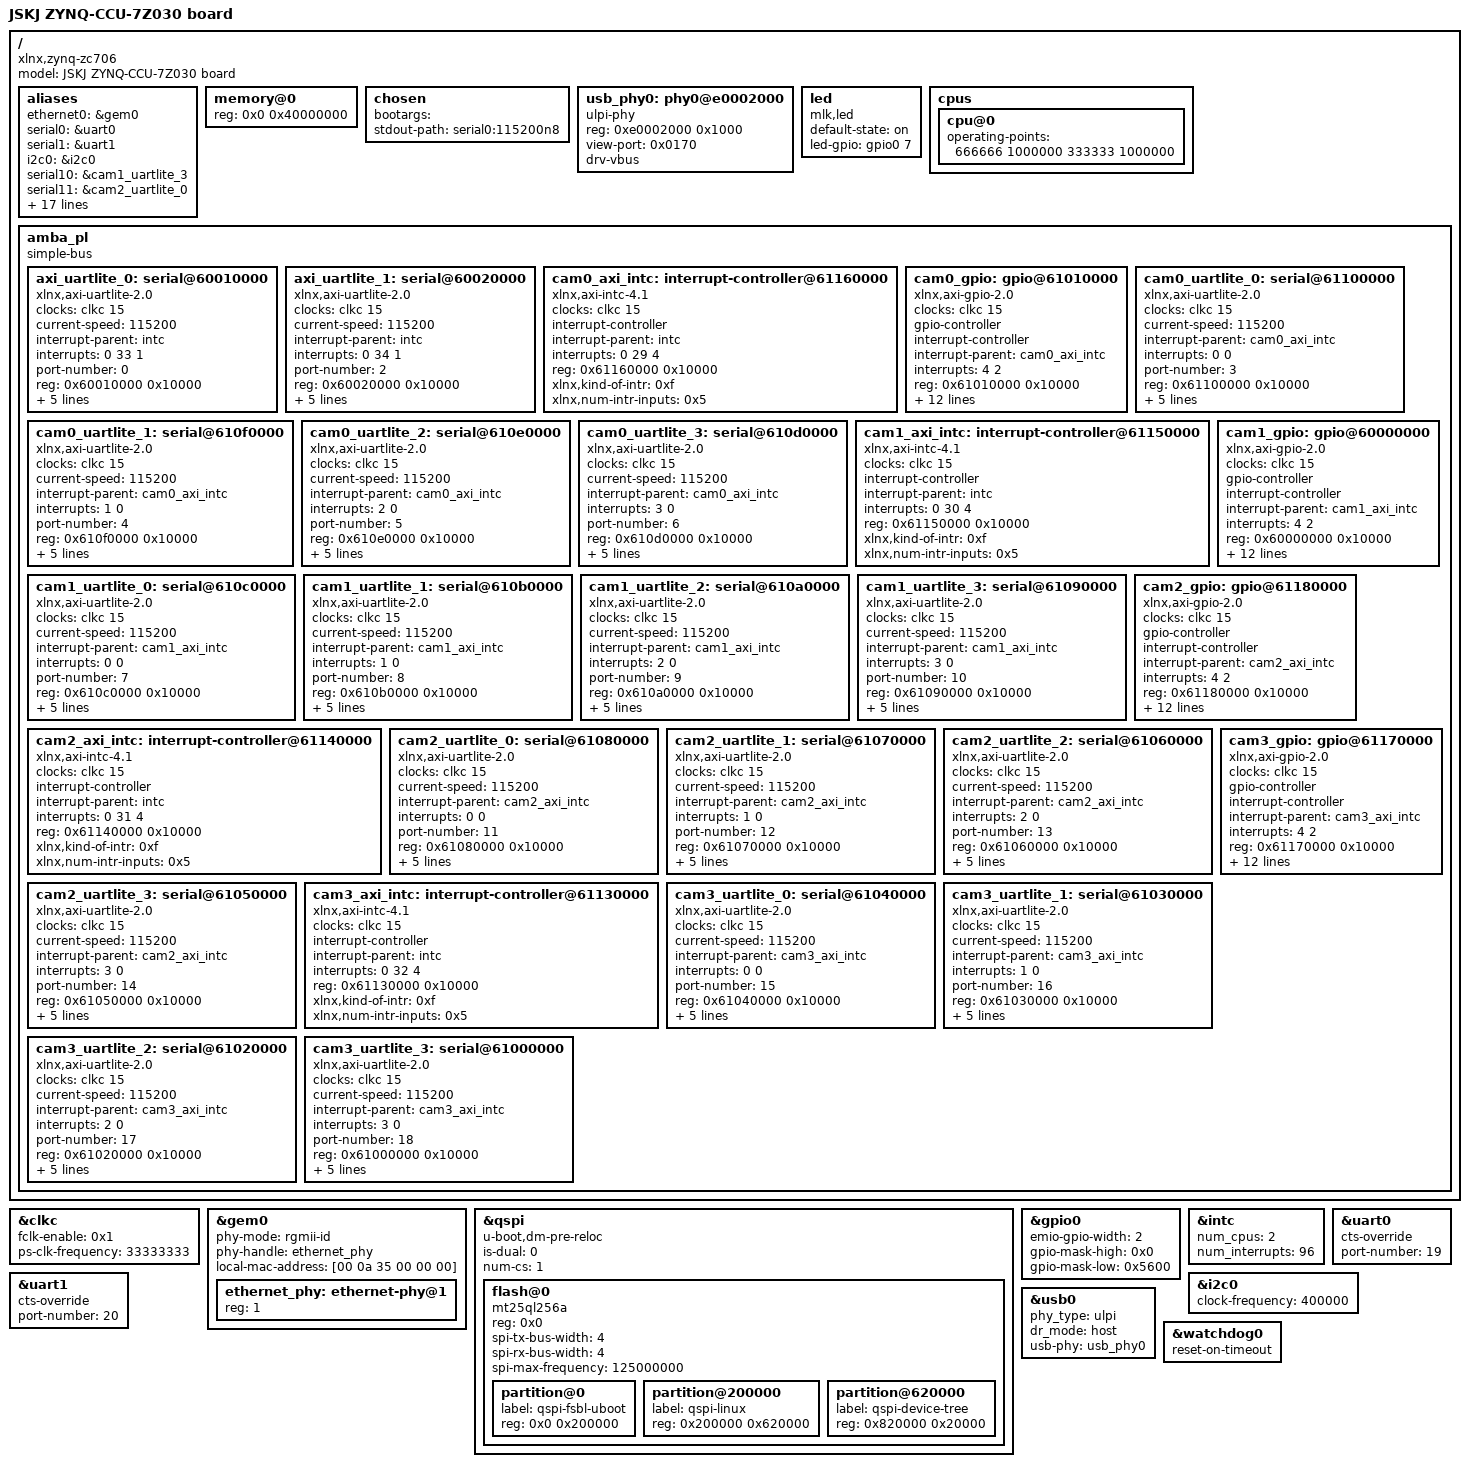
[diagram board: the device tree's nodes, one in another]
// SPDX-License-Identifier: GPL-2.0+
/*
 *  Copyright (C) 2011 - 2015 Xilinx
 *  Copyright (C) 2012 National Instruments Corp.
 */
#define GPIO_ACTIVE_HIGH 0
#define GPIO_ACTIVE_LOW 1

/dts-v1/;
#include "zynq-7000.dtsi"

/ {
	model = "JSKJ ZYNQ-CCU-7Z030 board";
	compatible = "xlnx,zynq-zc706", "xlnx,zynq-7000";

	aliases {
		ethernet0 = &gem0;
		serial0 = &uart0;
		serial1 = &uart1;
		i2c0 = &i2c0;
		serial10 = &cam1_uartlite_3;
		serial11 = &cam2_uartlite_0;
		serial12 = &cam2_uartlite_1;
		serial13 = &cam2_uartlite_2;
		serial14 = &cam2_uartlite_3;
		serial15 = &cam3_uartlite_0;
		serial16 = &cam3_uartlite_1;
		serial17 = &cam3_uartlite_2;
		serial18 = &cam3_uartlite_3;
		serial19 = &axi_uartlite_1;
		serial2 = &axi_uartlite_0;
		serial3 = &cam0_uartlite_0;
		serial4 = &cam0_uartlite_1;
		serial5 = &cam0_uartlite_2;
		serial6 = &cam0_uartlite_3;
		serial7 = &cam1_uartlite_0;
		serial8 = &cam1_uartlite_1;
		serial9 = &cam1_uartlite_2;
		spi0 = &qspi;
	};

	memory@0 {
		device_type = "memory";
		reg = <0x0 0x40000000>;
	};

	chosen {
		bootargs = "";
		stdout-path = "serial0:115200n8";
	};

	usb_phy0: phy0@e0002000 {
		compatible = "ulpi-phy";
		#phy-cells = <0>;
		reg = <0xe0002000 0x1000>;
		view-port = <0x0170>;
		drv-vbus;
	};

	led {
		compatible="mlk,led";
		status="okay";
		default-state="on";

		led-gpio = <&gpio0 7 GPIO_ACTIVE_HIGH>;
	};
};

/ {
	cpus {
		cpu@0 {
			operating-points = <666666 1000000 333333 1000000>;
		};
	};
};

/ {
	amba_pl: amba_pl {
		#address-cells = <1>;
		#size-cells = <1>;
		compatible = "simple-bus";
		ranges ;
		axi_uartlite_0: serial@60010000 {
			clock-names = "s_axi_aclk";
			clocks = <&clkc 15>;
			compatible = "xlnx,axi-uartlite-2.0", "xlnx,xps-uartlite-1.00.a";
			current-speed = <115200>;
			device_type = "serial";
			interrupt-names = "interrupt";
			interrupt-parent = <&intc>;
			interrupts = <0 33 1>;
			port-number = <0>;
			reg = <0x60010000 0x10000>;
			xlnx,baudrate = <0x1c200>;
			xlnx,data-bits = <0x8>;
			xlnx,odd-parity = <0x0>;
			xlnx,s-axi-aclk-freq-hz-d = "111.111115";
			xlnx,use-parity = <0x0>;
		};
		axi_uartlite_1: serial@60020000 {
			clock-names = "s_axi_aclk";
			clocks = <&clkc 15>;
			compatible = "xlnx,axi-uartlite-2.0", "xlnx,xps-uartlite-1.00.a";
			current-speed = <115200>;
			device_type = "serial";
			interrupt-names = "interrupt";
			interrupt-parent = <&intc>;
			interrupts = <0 34 1>;
			port-number = <2>;
			reg = <0x60020000 0x10000>;
			xlnx,baudrate = <0x1c200>;
			xlnx,data-bits = <0x8>;
			xlnx,odd-parity = <0x0>;
			xlnx,s-axi-aclk-freq-hz-d = "111.111115";
			xlnx,use-parity = <0x0>;
		};
		cam0_axi_intc: interrupt-controller@61160000 {
			#interrupt-cells = <2>;
			clock-names = "s_axi_aclk";
			clocks = <&clkc 15>;
			compatible = "xlnx,axi-intc-4.1", "xlnx,xps-intc-1.00.a";
			interrupt-controller ;
			interrupt-names = "irq";
			interrupt-parent = <&intc>;
			interrupts = <0 29 4>;
			reg = <0x61160000 0x10000>;
			xlnx,kind-of-intr = <0xf>;
			xlnx,num-intr-inputs = <0x5>;
		};
		cam0_gpio: gpio@61010000 {
			#gpio-cells = <2>;
			#interrupt-cells = <2>;
			clock-names = "s_axi_aclk";
			clocks = <&clkc 15>;
			compatible = "xlnx,axi-gpio-2.0", "xlnx,xps-gpio-1.00.a";
			gpio-controller ;
			interrupt-controller ;
			interrupt-names = "ip2intc_irpt";
			interrupt-parent = <&cam0_axi_intc>;
			interrupts = <4 2>;
			reg = <0x61010000 0x10000>;
			xlnx,all-inputs = <0x0>;
			xlnx,all-inputs-2 = <0x0>;
			xlnx,all-outputs = <0x0>;
			xlnx,all-outputs-2 = <0x0>;
			xlnx,dout-default = <0x00000000>;
			xlnx,dout-default-2 = <0x00000000>;
			xlnx,gpio-width = <0x8>;
			xlnx,gpio2-width = <0x20>;
			xlnx,interrupt-present = <0x1>;
			xlnx,is-dual = <0x0>;
			xlnx,tri-default = <0xFFFFFFFF>;
			xlnx,tri-default-2 = <0xFFFFFFFF>;
		};
		cam0_uartlite_0: serial@61100000 {
			clock-names = "s_axi_aclk";
			clocks = <&clkc 15>;
			compatible = "xlnx,axi-uartlite-2.0", "xlnx,xps-uartlite-1.00.a";
			current-speed = <115200>;
			device_type = "serial";
			interrupt-names = "interrupt";
			interrupt-parent = <&cam0_axi_intc>;
			interrupts = <0 0>;
			port-number = <3>;
			reg = <0x61100000 0x10000>;
			xlnx,baudrate = <0x1c200>;
			xlnx,data-bits = <0x8>;
			xlnx,odd-parity = <0x0>;
			xlnx,s-axi-aclk-freq-hz-d = "111.111115";
			xlnx,use-parity = <0x0>;
		};
		cam0_uartlite_1: serial@610f0000 {
			clock-names = "s_axi_aclk";
			clocks = <&clkc 15>;
			compatible = "xlnx,axi-uartlite-2.0", "xlnx,xps-uartlite-1.00.a";
			current-speed = <115200>;
			device_type = "serial";
			interrupt-names = "interrupt";
			interrupt-parent = <&cam0_axi_intc>;
			interrupts = <1 0>;
			port-number = <4>;
			reg = <0x610f0000 0x10000>;
			xlnx,baudrate = <0x1c200>;
			xlnx,data-bits = <0x8>;
			xlnx,odd-parity = <0x0>;
			xlnx,s-axi-aclk-freq-hz-d = "111.111115";
			xlnx,use-parity = <0x0>;
		};
		cam0_uartlite_2: serial@610e0000 {
			clock-names = "s_axi_aclk";
			clocks = <&clkc 15>;
			compatible = "xlnx,axi-uartlite-2.0", "xlnx,xps-uartlite-1.00.a";
			current-speed = <115200>;
			device_type = "serial";
			interrupt-names = "interrupt";
			interrupt-parent = <&cam0_axi_intc>;
			interrupts = <2 0>;
			port-number = <5>;
			reg = <0x610e0000 0x10000>;
			xlnx,baudrate = <0x1c200>;
			xlnx,data-bits = <0x8>;
			xlnx,odd-parity = <0x0>;
			xlnx,s-axi-aclk-freq-hz-d = "111.111115";
			xlnx,use-parity = <0x0>;
		};
		cam0_uartlite_3: serial@610d0000 {
			clock-names = "s_axi_aclk";
			clocks = <&clkc 15>;
			compatible = "xlnx,axi-uartlite-2.0", "xlnx,xps-uartlite-1.00.a";
			current-speed = <115200>;
			device_type = "serial";
			interrupt-names = "interrupt";
			interrupt-parent = <&cam0_axi_intc>;
			interrupts = <3 0>;
			port-number = <6>;
			reg = <0x610d0000 0x10000>;
			xlnx,baudrate = <0x1c200>;
			xlnx,data-bits = <0x8>;
			xlnx,odd-parity = <0x0>;
			xlnx,s-axi-aclk-freq-hz-d = "111.111115";
			xlnx,use-parity = <0x0>;
		};
		cam1_axi_intc: interrupt-controller@61150000 {
			#interrupt-cells = <2>;
			clock-names = "s_axi_aclk";
			clocks = <&clkc 15>;
			compatible = "xlnx,axi-intc-4.1", "xlnx,xps-intc-1.00.a";
			interrupt-controller ;
			interrupt-names = "irq";
			interrupt-parent = <&intc>;
			interrupts = <0 30 4>;
			reg = <0x61150000 0x10000>;
			xlnx,kind-of-intr = <0xf>;
			xlnx,num-intr-inputs = <0x5>;
		};
		cam1_gpio: gpio@60000000 {
			#gpio-cells = <2>;
			#interrupt-cells = <2>;
			clock-names = "s_axi_aclk";
			clocks = <&clkc 15>;
			compatible = "xlnx,axi-gpio-2.0", "xlnx,xps-gpio-1.00.a";
			gpio-controller ;
			interrupt-controller ;
			interrupt-names = "ip2intc_irpt";
			interrupt-parent = <&cam1_axi_intc>;
			interrupts = <4 2>;
			reg = <0x60000000 0x10000>;
			xlnx,all-inputs = <0x0>;
			xlnx,all-inputs-2 = <0x0>;
			xlnx,all-outputs = <0x0>;
			xlnx,all-outputs-2 = <0x0>;
			xlnx,dout-default = <0x00000000>;
			xlnx,dout-default-2 = <0x00000000>;
			xlnx,gpio-width = <0x8>;
			xlnx,gpio2-width = <0x20>;
			xlnx,interrupt-present = <0x1>;
			xlnx,is-dual = <0x0>;
			xlnx,tri-default = <0xFFFFFFFF>;
			xlnx,tri-default-2 = <0xFFFFFFFF>;
		};
		cam1_uartlite_0: serial@610c0000 {
			clock-names = "s_axi_aclk";
			clocks = <&clkc 15>;
			compatible = "xlnx,axi-uartlite-2.0", "xlnx,xps-uartlite-1.00.a";
			current-speed = <115200>;
			device_type = "serial";
			interrupt-names = "interrupt";
			interrupt-parent = <&cam1_axi_intc>;
			interrupts = <0 0>;
			port-number = <7>;
			reg = <0x610c0000 0x10000>;
			xlnx,baudrate = <0x1c200>;
			xlnx,data-bits = <0x8>;
			xlnx,odd-parity = <0x0>;
			xlnx,s-axi-aclk-freq-hz-d = "111.111115";
			xlnx,use-parity = <0x0>;
		};
		cam1_uartlite_1: serial@610b0000 {
			clock-names = "s_axi_aclk";
			clocks = <&clkc 15>;
			compatible = "xlnx,axi-uartlite-2.0", "xlnx,xps-uartlite-1.00.a";
			current-speed = <115200>;
			device_type = "serial";
			interrupt-names = "interrupt";
			interrupt-parent = <&cam1_axi_intc>;
			interrupts = <1 0>;
			port-number = <8>;
			reg = <0x610b0000 0x10000>;
			xlnx,baudrate = <0x1c200>;
			xlnx,data-bits = <0x8>;
			xlnx,odd-parity = <0x0>;
			xlnx,s-axi-aclk-freq-hz-d = "111.111115";
			xlnx,use-parity = <0x0>;
		};
		cam1_uartlite_2: serial@610a0000 {
			clock-names = "s_axi_aclk";
			clocks = <&clkc 15>;
			compatible = "xlnx,axi-uartlite-2.0", "xlnx,xps-uartlite-1.00.a";
			current-speed = <115200>;
			device_type = "serial";
			interrupt-names = "interrupt";
			interrupt-parent = <&cam1_axi_intc>;
			interrupts = <2 0>;
			port-number = <9>;
			reg = <0x610a0000 0x10000>;
			xlnx,baudrate = <0x1c200>;
			xlnx,data-bits = <0x8>;
			xlnx,odd-parity = <0x0>;
			xlnx,s-axi-aclk-freq-hz-d = "111.111115";
			xlnx,use-parity = <0x0>;
		};
		cam1_uartlite_3: serial@61090000 {
			clock-names = "s_axi_aclk";
			clocks = <&clkc 15>;
			compatible = "xlnx,axi-uartlite-2.0", "xlnx,xps-uartlite-1.00.a";
			current-speed = <115200>;
			device_type = "serial";
			interrupt-names = "interrupt";
			interrupt-parent = <&cam1_axi_intc>;
			interrupts = <3 0>;
			port-number = <10>;
			reg = <0x61090000 0x10000>;
			xlnx,baudrate = <0x1c200>;
			xlnx,data-bits = <0x8>;
			xlnx,odd-parity = <0x0>;
			xlnx,s-axi-aclk-freq-hz-d = "111.111115";
			xlnx,use-parity = <0x0>;
		};
		cam2_axi_intc: interrupt-controller@61140000 {
			#interrupt-cells = <2>;
			clock-names = "s_axi_aclk";
			clocks = <&clkc 15>;
			compatible = "xlnx,axi-intc-4.1", "xlnx,xps-intc-1.00.a";
			interrupt-controller ;
			interrupt-names = "irq";
			interrupt-parent = <&intc>;
			interrupts = <0 31 4>;
			reg = <0x61140000 0x10000>;
			xlnx,kind-of-intr = <0xf>;
			xlnx,num-intr-inputs = <0x5>;
		};
		cam2_gpio: gpio@61180000 {
			#gpio-cells = <2>;
			#interrupt-cells = <2>;
			clock-names = "s_axi_aclk";
			clocks = <&clkc 15>;
			compatible = "xlnx,axi-gpio-2.0", "xlnx,xps-gpio-1.00.a";
			gpio-controller ;
			interrupt-controller ;
			interrupt-names = "ip2intc_irpt";
			interrupt-parent = <&cam2_axi_intc>;
			interrupts = <4 2>;
			reg = <0x61180000 0x10000>;
			xlnx,all-inputs = <0x0>;
			xlnx,all-inputs-2 = <0x0>;
			xlnx,all-outputs = <0x0>;
			xlnx,all-outputs-2 = <0x0>;
			xlnx,dout-default = <0x00000000>;
			xlnx,dout-default-2 = <0x00000000>;
			xlnx,gpio-width = <0x8>;
			xlnx,gpio2-width = <0x20>;
			xlnx,interrupt-present = <0x1>;
			xlnx,is-dual = <0x0>;
			xlnx,tri-default = <0xFFFFFFFF>;
			xlnx,tri-default-2 = <0xFFFFFFFF>;
		};
		cam2_uartlite_0: serial@61080000 {
			clock-names = "s_axi_aclk";
			clocks = <&clkc 15>;
			compatible = "xlnx,axi-uartlite-2.0", "xlnx,xps-uartlite-1.00.a";
			current-speed = <115200>;
			device_type = "serial";
			interrupt-names = "interrupt";
			interrupt-parent = <&cam2_axi_intc>;
			interrupts = <0 0>;
			port-number = <11>;
			reg = <0x61080000 0x10000>;
			xlnx,baudrate = <0x1c200>;
			xlnx,data-bits = <0x8>;
			xlnx,odd-parity = <0x0>;
			xlnx,s-axi-aclk-freq-hz-d = "111.111115";
			xlnx,use-parity = <0x0>;
		};
		cam2_uartlite_1: serial@61070000 {
			clock-names = "s_axi_aclk";
			clocks = <&clkc 15>;
			compatible = "xlnx,axi-uartlite-2.0", "xlnx,xps-uartlite-1.00.a";
			current-speed = <115200>;
			device_type = "serial";
			interrupt-names = "interrupt";
			interrupt-parent = <&cam2_axi_intc>;
			interrupts = <1 0>;
			port-number = <12>;
			reg = <0x61070000 0x10000>;
			xlnx,baudrate = <0x1c200>;
			xlnx,data-bits = <0x8>;
			xlnx,odd-parity = <0x0>;
			xlnx,s-axi-aclk-freq-hz-d = "111.111115";
			xlnx,use-parity = <0x0>;
		};
		cam2_uartlite_2: serial@61060000 {
			clock-names = "s_axi_aclk";
			clocks = <&clkc 15>;
			compatible = "xlnx,axi-uartlite-2.0", "xlnx,xps-uartlite-1.00.a";
			current-speed = <115200>;
			device_type = "serial";
			interrupt-names = "interrupt";
			interrupt-parent = <&cam2_axi_intc>;
			interrupts = <2 0>;
			port-number = <13>;
			reg = <0x61060000 0x10000>;
			xlnx,baudrate = <0x1c200>;
			xlnx,data-bits = <0x8>;
			xlnx,odd-parity = <0x0>;
			xlnx,s-axi-aclk-freq-hz-d = "111.111115";
			xlnx,use-parity = <0x0>;
		};
		cam2_uartlite_3: serial@61050000 {
			clock-names = "s_axi_aclk";
			clocks = <&clkc 15>;
			compatible = "xlnx,axi-uartlite-2.0", "xlnx,xps-uartlite-1.00.a";
			current-speed = <115200>;
			device_type = "serial";
			interrupt-names = "interrupt";
			interrupt-parent = <&cam2_axi_intc>;
			interrupts = <3 0>;
			port-number = <14>;
			reg = <0x61050000 0x10000>;
			xlnx,baudrate = <0x1c200>;
			xlnx,data-bits = <0x8>;
			xlnx,odd-parity = <0x0>;
			xlnx,s-axi-aclk-freq-hz-d = "111.111115";
			xlnx,use-parity = <0x0>;
		};
		cam3_axi_intc: interrupt-controller@61130000 {
			#interrupt-cells = <2>;
			clock-names = "s_axi_aclk";
			clocks = <&clkc 15>;
			compatible = "xlnx,axi-intc-4.1", "xlnx,xps-intc-1.00.a";
			interrupt-controller ;
			interrupt-names = "irq";
			interrupt-parent = <&intc>;
			interrupts = <0 32 4>;
			reg = <0x61130000 0x10000>;
			xlnx,kind-of-intr = <0xf>;
			xlnx,num-intr-inputs = <0x5>;
		};
		cam3_gpio: gpio@61170000 {
			#gpio-cells = <2>;
			#interrupt-cells = <2>;
			clock-names = "s_axi_aclk";
			clocks = <&clkc 15>;
			compatible = "xlnx,axi-gpio-2.0", "xlnx,xps-gpio-1.00.a";
			gpio-controller ;
			interrupt-controller ;
			interrupt-names = "ip2intc_irpt";
			interrupt-parent = <&cam3_axi_intc>;
			interrupts = <4 2>;
			reg = <0x61170000 0x10000>;
			xlnx,all-inputs = <0x0>;
			xlnx,all-inputs-2 = <0x0>;
			xlnx,all-outputs = <0x0>;
			xlnx,all-outputs-2 = <0x0>;
			xlnx,dout-default = <0x00000000>;
			xlnx,dout-default-2 = <0x00000000>;
			xlnx,gpio-width = <0x8>;
			xlnx,gpio2-width = <0x20>;
			xlnx,interrupt-present = <0x1>;
			xlnx,is-dual = <0x0>;
			xlnx,tri-default = <0xFFFFFFFF>;
			xlnx,tri-default-2 = <0xFFFFFFFF>;
		};
		cam3_uartlite_0: serial@61040000 {
			clock-names = "s_axi_aclk";
			clocks = <&clkc 15>;
			compatible = "xlnx,axi-uartlite-2.0", "xlnx,xps-uartlite-1.00.a";
			current-speed = <115200>;
			device_type = "serial";
			interrupt-names = "interrupt";
			interrupt-parent = <&cam3_axi_intc>;
			interrupts = <0 0>;
			port-number = <15>;
			reg = <0x61040000 0x10000>;
			xlnx,baudrate = <0x1c200>;
			xlnx,data-bits = <0x8>;
			xlnx,odd-parity = <0x0>;
			xlnx,s-axi-aclk-freq-hz-d = "111.111115";
			xlnx,use-parity = <0x0>;
		};
		cam3_uartlite_1: serial@61030000 {
			clock-names = "s_axi_aclk";
			clocks = <&clkc 15>;
			compatible = "xlnx,axi-uartlite-2.0", "xlnx,xps-uartlite-1.00.a";
			current-speed = <115200>;
			device_type = "serial";
			interrupt-names = "interrupt";
			interrupt-parent = <&cam3_axi_intc>;
			interrupts = <1 0>;
			port-number = <16>;
			reg = <0x61030000 0x10000>;
			xlnx,baudrate = <0x1c200>;
			xlnx,data-bits = <0x8>;
			xlnx,odd-parity = <0x0>;
			xlnx,s-axi-aclk-freq-hz-d = "111.111115";
			xlnx,use-parity = <0x0>;
		};
		cam3_uartlite_2: serial@61020000 {
			clock-names = "s_axi_aclk";
			clocks = <&clkc 15>;
			compatible = "xlnx,axi-uartlite-2.0", "xlnx,xps-uartlite-1.00.a";
			current-speed = <115200>;
			device_type = "serial";
			interrupt-names = "interrupt";
			interrupt-parent = <&cam3_axi_intc>;
			interrupts = <2 0>;
			port-number = <17>;
			reg = <0x61020000 0x10000>;
			xlnx,baudrate = <0x1c200>;
			xlnx,data-bits = <0x8>;
			xlnx,odd-parity = <0x0>;
			xlnx,s-axi-aclk-freq-hz-d = "111.111115";
			xlnx,use-parity = <0x0>;
		};
		cam3_uartlite_3: serial@61000000 {
			clock-names = "s_axi_aclk";
			clocks = <&clkc 15>;
			compatible = "xlnx,axi-uartlite-2.0", "xlnx,xps-uartlite-1.00.a";
			current-speed = <115200>;
			device_type = "serial";
			interrupt-names = "interrupt";
			interrupt-parent = <&cam3_axi_intc>;
			interrupts = <3 0>;
			port-number = <18>;
			reg = <0x61000000 0x10000>;
			xlnx,baudrate = <0x1c200>;
			xlnx,data-bits = <0x8>;
			xlnx,odd-parity = <0x0>;
			xlnx,s-axi-aclk-freq-hz-d = "111.111115";
			xlnx,use-parity = <0x0>;
		};
	};
};

&clkc {
	fclk-enable = <0x1>;
	ps-clk-frequency = <33333333>;
};

&gem0 {
	status = "okay";
	phy-mode = "rgmii-id";
	phy-handle = <&ethernet_phy>;
	local-mac-address = [00 0a 35 00 00 00];
	ethernet_phy: ethernet-phy@1 {
		reg = <1>;
		device_type = "ethernet-phy";
	};
};


&qspi {
	u-boot,dm-pre-reloc;
	status = "okay";
	is-dual = <0>;
	num-cs = <1>;
	flash@0 {
		compatible = "mt25ql256a";
		reg = <0x0>;
		spi-tx-bus-width = <4>;
		spi-rx-bus-width = <4>;
		spi-max-frequency = <125000000>;
		#address-cells = <1>;
		#size-cells = <1>;
		partition@0 {
			label = "qspi-fsbl-uboot";
			reg = <0x0 0x200000>;
		};
		partition@200000 {
			label = "qspi-linux";
			reg = <0x200000 0x620000>;/* 0x420000 */
		};
		partition@620000 {
			label = "qspi-device-tree";
			reg = <0x820000 0x20000>;/* 0x620000 */
		};
		/*
		partition@640000 {
			label = "qspi-rootfs";
			reg = <0x640000 0x400000>;
		};
		*/
	};
};

&gpio0 {
	emio-gpio-width = <2>;
	gpio-mask-high = <0x0>;
	gpio-mask-low = <0x5600>;
};

&intc {
	num_cpus = <2>;
	num_interrupts = <96>;
};

&uart0 {
	cts-override ;
	device_type = "serial";
	port-number = <19>;
	status = "okay";
};

&uart1 {
	cts-override ;
	device_type = "serial";
	port-number = <20>;
	status = "okay";
};

&i2c0 {
	clock-frequency = <400000>;
	status = "okay";
};

&usb0 {
 	status = "okay";
	phy_type = "ulpi";
 	dr_mode = "host";
 	usb-phy = <&usb_phy0>;
 };

&watchdog0 {
	reset-on-timeout;
};
